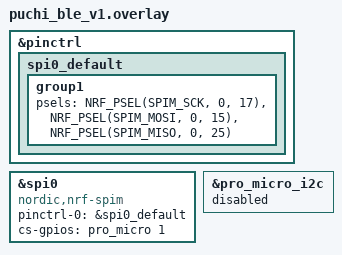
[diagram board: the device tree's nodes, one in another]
/*
 * Copyright (c) 2022 The ZMK Contributors
 *
 * SPDX-License-Identifier: MIT
 */

&pinctrl {
	spi0_default: spi0_default {
		group1 {
			psels = <NRF_PSEL(SPIM_SCK, 0, 17)>,
				<NRF_PSEL(SPIM_MOSI, 0, 15)>,
				<NRF_PSEL(SPIM_MISO, 0, 25)>;
		};
	};
};

nice_view_spi: &spi0 {
	compatible = "nordic,nrf-spim";
	pinctrl-0 = &spi0_default;
	pinctrl-names = "default";
	cs-gpios = <&pro_micro 1 GPIO_ACTIVE_HIGH>;
};

&pro_micro_i2c {
	status = "disabled";
};
